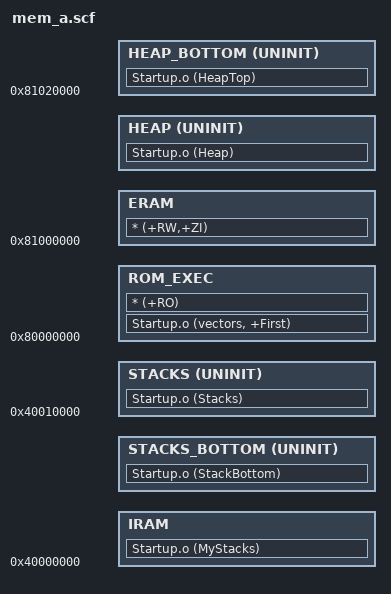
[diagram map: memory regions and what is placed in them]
;/****************************************Copyright (c)**************************************************
;**                               Guangzou ZLG-MCU Development Co.,LTD.
;**                                      graduate school
;**                                 http://www.zlgmcu.com
;**
;**--------------File Info-------------------------------------------------------------------------------
;** File Name: men_a.scf
;** Last modified Date:  2004-09-17
;** Last Version: 1.0
;** Descriptions: Scatter File
;**
;**------------------------------------------------------------------------------------------------------
;** Created By: Chenmingji
;** Created date:   2004-09-17
;** Version: 1.0
;** Descriptions: First version
;**
;**------------------------------------------------------------------------------------------------------
;** Modified by:
;** Modified date:
;** Version:
;** Descriptions:
;**
;********************************************************************************************************/

ROM_LOAD 0x80000000					;// Debug In External Flash
{
    ROM_EXEC 0x80000000				;// Entry point =  0x80000000		
    {								;// Code Space:0x80000000 ~ 0x80200000
        Startup.o (vectors, +First)
        * (+RO)
    }

    IRAM 0x40000000					;// Start Address Of Internal RAM
    {
        Startup.o (MyStacks)
    }

    STACKS_BOTTOM +0 UNINIT
    {
        Startup.o (StackBottom)
    }

    STACKS 0x40010000 UNINIT		;// The End Of Internal RAM
    {
        Startup.o (Stacks)
    }

    ERAM 0x81000000					;// Start Address Of External SRAM
    {
        * (+RW,+ZI)
    }

    HEAP +0 UNINIT
    {
        Startup.o (Heap)
    }

    HEAP_BOTTOM 0x81020000 UNINIT	;// The End Of External SRAM
    {
        Startup.o (HeapTop)
    }
}



